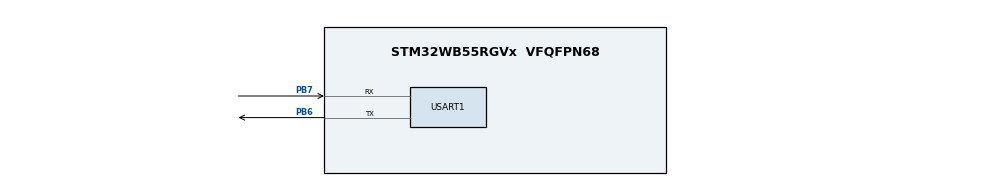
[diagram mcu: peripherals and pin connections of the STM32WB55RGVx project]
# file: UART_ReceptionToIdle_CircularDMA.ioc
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Dma.Request0=USART1_RX
Dma.USART1_RX.0.Direction=DMA_PERIPH_TO_MEMORY
Dma.USART1_RX.0.EventEnable=DISABLE
Dma.USART1_RX.0.Instance=DMA1_Channel1
Dma.USART1_RX.0.MemDataAlignment=DMA_MDATAALIGN_BYTE
Dma.USART1_RX.0.MemInc=DMA_MINC_ENABLE
Dma.USART1_RX.0.Mode=DMA_CIRCULAR
Dma.USART1_RX.0.PeriphDataAlignment=DMA_PDATAALIGN_BYTE
Dma.USART1_RX.0.PeriphInc=DMA_PINC_DISABLE
Dma.USART1_RX.0.Polarity=HAL_DMAMUX_REQ_GEN_RISING
Dma.USART1_RX.0.Priority=DMA_PRIORITY_LOW
Dma.USART1_RX.0.RequestNumber=1
Dma.USART1_RX.0.SignalID=NONE
Dma.USART1_RX.0.SyncEnable=DISABLE
Dma.USART1_RX.0.SyncPolarity=HAL_DMAMUX_SYNC_NO_EVENT
Dma.USART1_RX.0.SyncRequestNumber=1
Dma.USART1_RX.0.SyncSignalID=NONE
Mcu.Family=STM32WB
Mcu.Name=STM32WB55RGVx
Mcu.Package=VFQFPN68
NVIC.DMA1_Channel1_IRQn=true\:0\:0\:false\:false\:true\:false\:true
NVIC.PriorityGroup=NVIC_PRIORITYGROUP_4
NVIC.USART1_IRQn=true\:0\:0\:false\:false\:true\:true\:true
PB6.GPIO_PuPd=GPIO_PULLUP
PB6.Mode=Asynchronous
PB6.Signal=USART1_TX
PB7.GPIO_PuPd=GPIO_PULLUP
PB7.Mode=Asynchronous
PB7.Signal=USART1_RX
ProjectManager.HeapSize=0x200
ProjectManager.StackSize=0x400
ProjectManager.TargetToolchain=EWARM V8.32
RCC.AHB2CLKDivider=RCC_SYSCLK_DIV2
RCC.AHBFreq_Value=64000000
RCC.APB1Freq_Value=64000000
RCC.APB1TimFreq_Value=64000000
RCC.APB2Freq_Value=64000000
RCC.APB2TimFreq_Value=64000000
RCC.APB3Freq_Value=16000000
RCC.CortexFreq_Value=64000000
RCC.HCLKFreq_Value=64000000
RCC.HSE_VALUE=8000000
RCC.HSI48_VALUE=48000000
RCC.HSI_VALUE=16000000
RCC.LSE_VALUE=32768
RCC.PLLN=32
RCC.SYSCLKFreq_VALUE=64000000
RCC.SYSCLKSource=RCC_SYSCLKSOURCE_PLLCLK
RCC.VCOOutputFreq_Value=128000000
USART1.VirtualMode-Asynchronous=VM_ASYNC
board=custom

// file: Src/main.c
/* USER CODE BEGIN Header */
/**
  ******************************************************************************
  * @file           : main.c
  * @brief          : Main program body
  ******************************************************************************
  * @attention
  *
  * <h2><center>&copy; Copyright (c) 2019 STMicroelectronics.
  * All rights reserved.</center></h2>
  *
  * This software component is licensed by ST under BSD 3-Clause license,
  * the "License"; You may not use this file except in compliance with the
  * License. You may obtain a copy of the License at:
  *                        opensource.org/licenses/BSD-3-Clause
  *
  ******************************************************************************
  */
/* USER CODE END Header */
#include "main.h"

UART_HandleTypeDef huart1;
DMA_HandleTypeDef hdma_usart1_rx;

/* USER CODE BEGIN PV */
/**
  * @brief Text strings printed on PC Com port for user information
  */
uint8_t aTextInfoStart[] = "\r\nUSART Example : Enter characters to fill reception buffers.\r\n";

uint8_t aRXBufferUser[RX_BUFFER_SIZE];

/**
  * @brief Data buffers used to manage received data in interrupt routine
  */
uint8_t aRXBufferA[RX_BUFFER_SIZE];
uint8_t aRXBufferB[RX_BUFFER_SIZE];

__IO uint32_t     uwNbReceivedChars;
uint8_t *pBufferReadyForUser;
uint8_t *pBufferReadyForReception;

/* USER CODE END PV */

void SystemClock_Config(void);
static void MX_GPIO_Init(void);
static void MX_DMA_Init(void);
static void MX_USART1_UART_Init(void);
/* USER CODE BEGIN PFP */
void PrintInfo(UART_HandleTypeDef *huart, uint8_t *String, uint16_t Size);
void StartReception(void);
void UserDataTreatment(UART_HandleTypeDef *huart, uint8_t* pData, uint16_t Size);

/* USER CODE END PFP */

int main(void)
{
  /* USER CODE BEGIN 1 */
  /* STM32WBxx HAL library initialization:
       - Configure the Flash prefetch
       - Systick timer is configured by default as source of time base, but user
         can eventually implement his proper time base source (a general purpose
         timer for example or other time source), keeping in mind that Time base
         duration should be kept 1ms since PPP_TIMEOUT_VALUEs are defined and
         handled in milliseconds basis.
       - Set NVIC Group Priority to 4
       - Low Level Initialization
     */
  /* USER CODE END 1 */

  /* MCU Configuration--------------------------------------------------------*/

  /* Reset of all peripherals, Initializes the Flash interface and the Systick. */
  HAL_Init();

  /* Configure the system clock */
  SystemClock_Config();

  /* Initialize all configured peripherals */
  MX_GPIO_Init();
  MX_DMA_Init();
  MX_USART1_UART_Init();
  /* USER CODE BEGIN 2 */

  /* Initiate Continuous reception */
  StartReception();

  /* USER CODE END 2 */

  /* Infinite loop */
  while (1)
  {

  }
}

void SystemClock_Config(void)
{
  RCC_OscInitTypeDef RCC_OscInitStruct = {0};
  RCC_ClkInitTypeDef RCC_ClkInitStruct = {0};
  RCC_PeriphCLKInitTypeDef PeriphClkInitStruct = {0};

  /** Configure the main internal regulator output voltage
  */
  __HAL_PWR_VOLTAGESCALING_CONFIG(PWR_REGULATOR_VOLTAGE_SCALE1);
  /** Initializes the RCC Oscillators according to the specified parameters
  * in the RCC_OscInitTypeDef structure.
  */
  RCC_OscInitStruct.OscillatorType = RCC_OSCILLATORTYPE_HSI|RCC_OSCILLATORTYPE_MSI;
  RCC_OscInitStruct.HSIState = RCC_HSI_ON;
  RCC_OscInitStruct.MSIState = RCC_MSI_ON;
  RCC_OscInitStruct.HSICalibrationValue = RCC_HSICALIBRATION_DEFAULT;
  RCC_OscInitStruct.MSICalibrationValue = RCC_MSICALIBRATION_DEFAULT;
  RCC_OscInitStruct.MSIClockRange = RCC_MSIRANGE_6;
  RCC_OscInitStruct.PLL.PLLState = RCC_PLL_ON;
  RCC_OscInitStruct.PLL.PLLSource = RCC_PLLSOURCE_MSI;
  RCC_OscInitStruct.PLL.PLLM = RCC_PLLM_DIV1;
  RCC_OscInitStruct.PLL.PLLN = 32;
  RCC_OscInitStruct.PLL.PLLP = RCC_PLLP_DIV2;
  RCC_OscInitStruct.PLL.PLLR = RCC_PLLR_DIV2;
  RCC_OscInitStruct.PLL.PLLQ = RCC_PLLQ_DIV2;
  if (HAL_RCC_OscConfig(&RCC_OscInitStruct) != HAL_OK)
  {
    Error_Handler();
  }
  /** Configure the SYSCLKSource, HCLK, PCLK1 and PCLK2 clocks dividers
  */
  RCC_ClkInitStruct.ClockType = RCC_CLOCKTYPE_HCLK4|RCC_CLOCKTYPE_HCLK2
                              |RCC_CLOCKTYPE_HCLK|RCC_CLOCKTYPE_SYSCLK
                              |RCC_CLOCKTYPE_PCLK1|RCC_CLOCKTYPE_PCLK2;
  RCC_ClkInitStruct.SYSCLKSource = RCC_SYSCLKSOURCE_PLLCLK;
  RCC_ClkInitStruct.AHBCLKDivider = RCC_SYSCLK_DIV1;
  RCC_ClkInitStruct.APB1CLKDivider = RCC_HCLK_DIV1;
  RCC_ClkInitStruct.APB2CLKDivider = RCC_HCLK_DIV1;
  RCC_ClkInitStruct.AHBCLK2Divider = RCC_SYSCLK_DIV2;
  RCC_ClkInitStruct.AHBCLK4Divider = RCC_SYSCLK_DIV1;

  if (HAL_RCC_ClockConfig(&RCC_ClkInitStruct, FLASH_LATENCY_3) != HAL_OK)
  {
    Error_Handler();
  }
  /** Initializes the peripherals clocks
  */
  PeriphClkInitStruct.PeriphClockSelection = RCC_PERIPHCLK_SMPS|RCC_PERIPHCLK_USART1;
  PeriphClkInitStruct.Usart1ClockSelection = RCC_USART1CLKSOURCE_PCLK2;
  PeriphClkInitStruct.SmpsClockSelection = RCC_SMPSCLKSOURCE_HSI;
  PeriphClkInitStruct.SmpsDivSelection = RCC_SMPSCLKDIV_RANGE1;
  if (HAL_RCCEx_PeriphCLKConfig(&PeriphClkInitStruct) != HAL_OK)
  {
    Error_Handler();
  }
}

static void MX_USART1_UART_Init(void)
{

  huart1.Instance = USART1;
  huart1.Init.BaudRate = 115200;
  huart1.Init.WordLength = UART_WORDLENGTH_8B;
  huart1.Init.StopBits = UART_STOPBITS_1;
  huart1.Init.Parity = UART_PARITY_NONE;
  huart1.Init.Mode = UART_MODE_TX_RX;
  huart1.Init.HwFlowCtl = UART_HWCONTROL_NONE;
  huart1.Init.OverSampling = UART_OVERSAMPLING_16;
  huart1.Init.OneBitSampling = UART_ONE_BIT_SAMPLE_DISABLE;
  huart1.Init.ClockPrescaler = UART_PRESCALER_DIV1;
  huart1.AdvancedInit.AdvFeatureInit = UART_ADVFEATURE_NO_INIT;
  if (HAL_UART_Init(&huart1) != HAL_OK)
  {
    Error_Handler();
  }
  if (HAL_UARTEx_SetTxFifoThreshold(&huart1, UART_TXFIFO_THRESHOLD_1_8) != HAL_OK)
  {
    Error_Handler();
  }
  if (HAL_UARTEx_SetRxFifoThreshold(&huart1, UART_RXFIFO_THRESHOLD_1_8) != HAL_OK)
  {
    Error_Handler();
  }
  if (HAL_UARTEx_DisableFifoMode(&huart1) != HAL_OK)
  {
    Error_Handler();
  }

}

static void MX_DMA_Init(void)
{

  /* DMA controller clock enable */
  __HAL_RCC_DMAMUX1_CLK_ENABLE();
  __HAL_RCC_DMA1_CLK_ENABLE();

  /* DMA interrupt init */
  /* DMA1_Channel1_IRQn interrupt configuration */
  HAL_NVIC_SetPriority(DMA1_Channel1_IRQn, 0, 0);
  HAL_NVIC_EnableIRQ(DMA1_Channel1_IRQn);

}

static void MX_GPIO_Init(void)
{

  /* GPIO Ports Clock Enable */
  __HAL_RCC_GPIOB_CLK_ENABLE();

}

/* USER CODE BEGIN 4 */
/**
  * @brief  Send Txt information message on UART Tx line (to PC Com port).
  * @param  huart UART handle.
  * @param  String String to be sent to user display
  * @param  Size   Size of string
  * @retval None
  */
void PrintInfo(UART_HandleTypeDef *huart, uint8_t *String, uint16_t Size)
{
  if (HAL_OK != HAL_UART_Transmit(huart, String, Size, 100))
  {
    Error_Handler();
  }
}

/**
  * @brief  This function prints user info on PC com port and initiates RX transfer
  * @retval None
  */
void StartReception(void)
{
  /* Initializes Buffer swap mechanism (used in User callback) :
     - 2 physical buffers aRXBufferA and aRXBufferB (RX_BUFFER_SIZE length)
  */
  pBufferReadyForReception = aRXBufferA;
  pBufferReadyForUser      = aRXBufferB;
  uwNbReceivedChars        = 0;

  /* Print user info on PC com port */
  PrintInfo(&huart1, aTextInfoStart, COUNTOF(aTextInfoStart));

  /* Initializes Rx sequence using Reception To Idle event API.
     As DMA channel associated to UART Rx is configured as Circular,
     reception is endless.
     If reception has to be stopped, call to HAL_UART_AbortReceive() could be used.

     Use of HAL_UARTEx_ReceiveToIdle_DMA service, will generate calls to
     user defined HAL_UARTEx_RxEventCallback callback for each occurrence of
     following events :
     - DMA RX Half Transfer event (HT)
     - DMA RX Transfer Complete event (TC)
     - IDLE event on UART Rx line (indicating a pause is UART reception flow)
  */
  if (HAL_OK != HAL_UARTEx_ReceiveToIdle_DMA(&huart1, aRXBufferUser, RX_BUFFER_SIZE))
  {
    Error_Handler();
  }
}

/**
  * @brief  This function handles buffer containing received data on PC com port
  * @note   In this example, received data are sent back on UART Tx (loopback)
  *         Any other processing such as copying received data in a larger buffer to make it
  *         available for application, could be implemented here.
  * @note   This routine is executed in Interrupt context.
  * @param  huart UART handle.
  * @param  pData Pointer on received data buffer to be processed
  * @retval Size  Nb of received characters available in buffer
  */
void UserDataTreatment(UART_HandleTypeDef *huart, uint8_t* pData, uint16_t Size)
{
  /*
   * This function might be called in any of the following interrupt contexts :
   *  - DMA TC and HT events
   *  - UART IDLE line event
   *
   * pData and Size defines the buffer where received data have been copied, in order to be processed.
   * During this processing of already received data, reception is still ongoing.
   *
   */
  uint8_t* pBuff = pData;
  uint8_t  i;

  /* Implementation of loopback is on purpose implemented in direct register access,
     in order to be able to echo received characters as fast as they are received.
     Wait for TC flag to be raised at end of transmit is then removed, only TXE is checked */
  for (i = 0; i < Size; i++)
  {
    while (!(__HAL_UART_GET_FLAG(huart, UART_FLAG_TXE))) {}
    huart->Instance->TDR = *pBuff;
    pBuff++;
  }

}

/**
  * @brief  User implementation of the Reception Event Callback
  *         (Rx event notification called after use of advanced reception service).
  * @param  huart UART handle
  * @param  Size  Number of data available in application reception buffer (indicates a position in
  *               reception buffer until which, data are available)
  * @retval None
  */
void HAL_UARTEx_RxEventCallback(UART_HandleTypeDef *huart, uint16_t Size)
{
  static uint8_t old_pos = 0;
  uint8_t *ptemp;
  uint8_t i;

  /* Check if number of received data in recpetion buffer has changed */
  if (Size != old_pos)
  {
    /* Check if position of index in reception buffer has simply be increased
       of if end of buffer has been reached */
    if (Size > old_pos)
    {
      /* Current position is higher than previous one */
      uwNbReceivedChars = Size - old_pos;
      /* Copy received data in "User" buffer for evacuation */
      for (i = 0; i < uwNbReceivedChars; i++)
      {
        pBufferReadyForUser[i] = aRXBufferUser[old_pos + i];
      }
    }
    else
    {
      /* Current position is lower than previous one : end of buffer has been reached */
      /* First copy data from current position till end of buffer */
      uwNbReceivedChars = RX_BUFFER_SIZE - old_pos;
      /* Copy received data in "User" buffer for evacuation */
      for (i = 0; i < uwNbReceivedChars; i++)
      {
        pBufferReadyForUser[i] = aRXBufferUser[old_pos + i];
      }
      /* Check and continue with beginning of buffer */
      if (Size > 0)
      {
        for (i = 0; i < Size; i++)
        {
          pBufferReadyForUser[uwNbReceivedChars + i] = aRXBufferUser[i];
        }
        uwNbReceivedChars += Size;
      }
    }
    /* Process received data that has been extracted from Rx User buffer */
    UserDataTreatment(huart, pBufferReadyForUser, uwNbReceivedChars);

    /* Swap buffers for next bytes to be processed */
    ptemp = pBufferReadyForUser;
    pBufferReadyForUser = pBufferReadyForReception;
    pBufferReadyForReception = ptemp;
  }
  /* Update old_pos as new reference of position in User Rx buffer that
     indicates position to which data have been processed */
  old_pos = Size;

}

/* USER CODE END 4 */

void Error_Handler(void)
{
  /* USER CODE BEGIN Error_Handler_Debug */
  /* User can add his own implementation to report the HAL error return state */
  /* Turn LED3 on */
  BSP_LED_On(LED3);
  while (1);
  /* USER CODE END Error_Handler_Debug */
}

/************************ (C) COPYRIGHT STMicroelectronics *****END OF FILE****/
